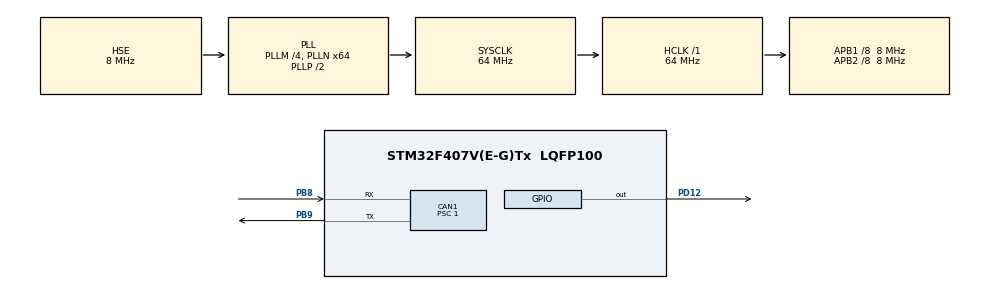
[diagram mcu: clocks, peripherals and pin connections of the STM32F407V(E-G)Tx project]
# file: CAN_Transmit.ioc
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CAN1.BS1=CAN_BS1_6TQ
CAN1.CalculateBaudRate=1000000
CAN1.CalculateTimeBit=1000
CAN1.CalculateTimeQuantum=125.0
CAN1.Prescaler=1
Mcu.Family=STM32F4
Mcu.Name=STM32F407V(E-G)Tx
Mcu.Package=LQFP100
NVIC.PriorityGroup=NVIC_PRIORITYGROUP_0
PB8.GPIO_PuPd=GPIO_PULLUP
PB8.Mode=CAN_Activate
PB8.Signal=CAN1_RX
PB9.GPIO_PuPd=GPIO_PULLUP
PB9.Mode=CAN_Activate
PB9.Signal=CAN1_TX
PD12.Signal=GPIO_Output
PH0-OSC_IN.Mode=HSE-External-Oscillator
PH0-OSC_IN.Signal=RCC_OSC_IN
PH1-OSC_OUT.Mode=HSE-External-Oscillator
PH1-OSC_OUT.Signal=RCC_OSC_OUT
ProjectManager.HeapSize=0x200
ProjectManager.StackSize=0x400
ProjectManager.TargetToolchain=STM32CubeIDE
RCC.48MHZClocksFreq_Value=18285714.285714287
RCC.AHBFreq_Value=64000000
RCC.APB1CLKDivider=RCC_HCLK_DIV8
RCC.APB1Freq_Value=8000000
RCC.APB1TimFreq_Value=16000000
RCC.APB2CLKDivider=RCC_HCLK_DIV8
RCC.APB2Freq_Value=8000000
RCC.APB2TimFreq_Value=16000000
RCC.CortexFreq_Value=64000000
RCC.HCLKFreq_Value=64000000
RCC.HSE_VALUE=8000000
RCC.HSI_VALUE=16000000
RCC.LSE_VALUE=32768
RCC.PLLM=4
RCC.PLLN=64
RCC.PLLQ=7
RCC.PLLSourceVirtual=RCC_PLLSOURCE_HSE
RCC.SYSCLKFreq_VALUE=64000000
RCC.SYSCLKSource=RCC_SYSCLKSOURCE_PLLCLK
RCC.VCOOutputFreq_Value=128000000
board=STM32F407G-DISC1

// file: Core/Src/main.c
/* USER CODE BEGIN Header */
/**
  ******************************************************************************
  * @file           : main.c
  * @brief          : Main program body
  ******************************************************************************
  * @attention
  *
  * Copyright (c) 2025 STMicroelectronics.
  * All rights reserved.
  *
  * This software is licensed under terms that can be found in the LICENSE file
  * in the root directory of this software component.
  * If no LICENSE file comes with this software, it is provided AS-IS.
  *
  ******************************************************************************
  */
/* USER CODE END Header */
#include "main.h"

CAN_HandleTypeDef hcan1; //Structure principale contenant la configuration matérielle du CAN

/* USER CODE BEGIN PV */
CAN_TxHeaderTypeDef   TxHeader; //En-tête de trame (type ID, taille, mode RTR/STD/EXT...)
uint8_t               TxData[1];
uint32_t              TxMailbox;
/* USER CODE END PV */

void SystemClock_Config(void);
static void MX_GPIO_Init(void);
static void MX_CAN1_Init(void);

int main(void)
{

  /* MCU Configuration--------------------------------------------------------*/

  /* Reset of all peripherals, Initializes the Flash interface and the Systick. */
  HAL_Init();

  /* Configure the system clock */
  SystemClock_Config();

  /* Initialize all configured peripherals */
  MX_GPIO_Init();
  MX_CAN1_Init();
  /* USER CODE BEGIN 2 */
    TxHeader.DLC = 1; // data length
    TxHeader.IDE = CAN_ID_STD;
    TxHeader.RTR = CAN_RTR_DATA;
    TxHeader.StdId = 0x01; // ID
    if(HAL_CAN_Start(&hcan1)!=HAL_OK)
    {
    	Error_Handler();
    }

    TxData[0]=40;

  /* USER CODE END 2 */

  /* Infinite loop */
  while (1)
  {

	  HAL_CAN_AddTxMessage(&hcan1, &TxHeader, TxData, &TxMailbox);
	  HAL_GPIO_TogglePin(GPIOD, GPIO_PIN_12);
	  HAL_Delay(500);
  }
}

void SystemClock_Config(void)
{
  RCC_OscInitTypeDef RCC_OscInitStruct = {0};
  RCC_ClkInitTypeDef RCC_ClkInitStruct = {0};

  /** Configure the main internal regulator output voltage
  */
  __HAL_RCC_PWR_CLK_ENABLE();
  __HAL_PWR_VOLTAGESCALING_CONFIG(PWR_REGULATOR_VOLTAGE_SCALE1);

  /** Initializes the RCC Oscillators according to the specified parameters
  * in the RCC_OscInitTypeDef structure.
  */
  RCC_OscInitStruct.OscillatorType = RCC_OSCILLATORTYPE_HSE;
  RCC_OscInitStruct.HSEState = RCC_HSE_ON;
  RCC_OscInitStruct.PLL.PLLState = RCC_PLL_ON;
  RCC_OscInitStruct.PLL.PLLSource = RCC_PLLSOURCE_HSE;
  RCC_OscInitStruct.PLL.PLLM = 4;
  RCC_OscInitStruct.PLL.PLLN = 64;
  RCC_OscInitStruct.PLL.PLLP = RCC_PLLP_DIV2;
  RCC_OscInitStruct.PLL.PLLQ = 7;
  if (HAL_RCC_OscConfig(&RCC_OscInitStruct) != HAL_OK)
  {
    Error_Handler();
  }

  /** Initializes the CPU, AHB and APB buses clocks
  */
  RCC_ClkInitStruct.ClockType = RCC_CLOCKTYPE_HCLK|RCC_CLOCKTYPE_SYSCLK
                              |RCC_CLOCKTYPE_PCLK1|RCC_CLOCKTYPE_PCLK2;
  RCC_ClkInitStruct.SYSCLKSource = RCC_SYSCLKSOURCE_PLLCLK;
  RCC_ClkInitStruct.AHBCLKDivider = RCC_SYSCLK_DIV1;
  RCC_ClkInitStruct.APB1CLKDivider = RCC_HCLK_DIV8;
  RCC_ClkInitStruct.APB2CLKDivider = RCC_HCLK_DIV8;

  if (HAL_RCC_ClockConfig(&RCC_ClkInitStruct, FLASH_LATENCY_2) != HAL_OK)
  {
    Error_Handler();
  }
}

static void MX_CAN1_Init(void)
{

  hcan1.Instance = CAN1;
  hcan1.Init.Prescaler = 1;
  hcan1.Init.Mode = CAN_MODE_NORMAL;
  hcan1.Init.SyncJumpWidth = CAN_SJW_1TQ;
  hcan1.Init.TimeSeg1 = CAN_BS1_6TQ;
  hcan1.Init.TimeSeg2 = CAN_BS2_1TQ;
  hcan1.Init.TimeTriggeredMode = DISABLE;
  hcan1.Init.AutoBusOff = DISABLE;
  hcan1.Init.AutoWakeUp = DISABLE;
  hcan1.Init.AutoRetransmission = DISABLE;
  hcan1.Init.ReceiveFifoLocked = DISABLE;
  hcan1.Init.TransmitFifoPriority = DISABLE;
  if (HAL_CAN_Init(&hcan1) != HAL_OK)
  {
    Error_Handler();
  }

}

static void MX_GPIO_Init(void)
{
  GPIO_InitTypeDef GPIO_InitStruct = {0};

  /* GPIO Ports Clock Enable */
  __HAL_RCC_GPIOH_CLK_ENABLE();
  __HAL_RCC_GPIOD_CLK_ENABLE();
  __HAL_RCC_GPIOB_CLK_ENABLE();

  /*Configure GPIO pin Output Level */
  HAL_GPIO_WritePin(GPIOD, GPIO_PIN_12, GPIO_PIN_RESET);

  /*Configure GPIO pin : PD12 */
  GPIO_InitStruct.Pin = GPIO_PIN_12;
  GPIO_InitStruct.Mode = GPIO_MODE_OUTPUT_PP;
  GPIO_InitStruct.Pull = GPIO_NOPULL;
  GPIO_InitStruct.Speed = GPIO_SPEED_FREQ_LOW;
  HAL_GPIO_Init(GPIOD, &GPIO_InitStruct);

}

void Error_Handler(void)
{
  __disable_irq();
  while (1)
  {
  }
}
